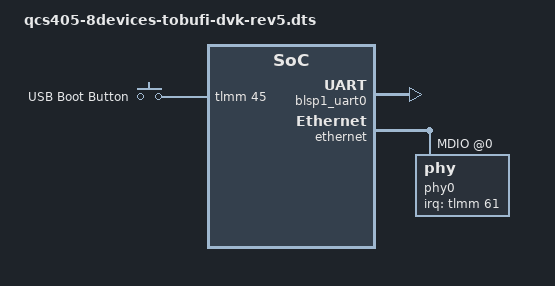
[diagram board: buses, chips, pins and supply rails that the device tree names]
// SPDX-License-Identifier: GPL-2.0
/*
 * Copyright (c) 2026 8devices, UAB
 */

/dts-v1/;

#include <dt-bindings/interrupt-controller/irq.h>
#include "qcs405-8devices-tobufi-dvk.dts"

/ {
	/* IOT (0x20) TobuFi-DVK (0x81) HWrev (5.0) */
	qcom,board-id = <0x81050020 0x0>;

	aliases {
		serial0 = &blsp1_uart2;
		serial1 = &blsp1_uart0;
		serial2 = &blsp1_uart1;
		serial3 = &blsp2_uart0;
	};

	/* Force-USB-boot button, wired from rev4 onwards. */
	gpio-keys {
		compatible = "gpio-keys";
		pinctrl-names = "default";
		pinctrl-0 = <&gpio_keys>;

		usb-boot@45 {
			label = "USB Boot Button";
			linux,code = <BTN_0>;
			gpios = <&tlmm 45 GPIO_ACTIVE_HIGH>;
		};
	};
};

&tlmm {
	gpio_keys: gpio-keys-pins {
		pins = "gpio45";
		function = "gpio";
		bias-pull-down;
		drive-strength = <2>;
		input-enable;
	};
};

&ethernet_default {
	phy-intr-pins {
		pins = "gpio61";
		function = "rgmii_int";
		bias-disable;
		input-enable;
	};
};

/* BLSP0, 4-pin connector */
&blsp1_uart0 {
	status = "okay";
};

&ethernet {
	mdio {
		phy0: phy@0 {
			interrupt-parent = <&tlmm>;
			interrupts = <61 IRQ_TYPE_LEVEL_LOW>;
		};
	};
};
